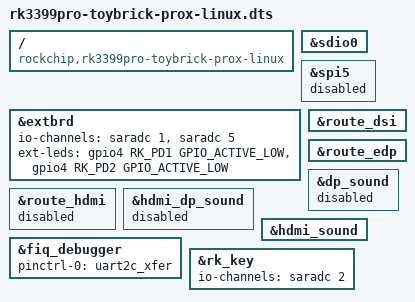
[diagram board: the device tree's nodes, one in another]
/*
 * Copyright (c) 2019 Fuzhou Rockchip Electronics Co., Ltd
 *
 * This file is dual-licensed: you can use it either under the terms
 * of the GPL or the X11 license, at your option. Note that this dual
 * licensing only applies to this file, and not this project as a
 * whole.
 *
 *  a) This file is free software; you can redistribute it and/or
 *     modify it under the terms of the GNU General Public License as
 *     published by the Free Software Foundation; either version 2 of the
 *     License, or (at your option) any later version.
 *
 *     This file is distributed in the hope that it will be useful,
 *     but WITHOUT ANY WARRANTY; without even the implied warranty of
 *     MERCHANTABILITY or FITNESS FOR A PARTICULAR PURPOSE.  See the
 *     GNU General Public License for more details.
 *
 * Or, alternatively,
 *
 *  b) Permission is hereby granted, free of charge, to any person
 *     obtaining a copy of this software and associated documentation
 *     files (the "Software"), to deal in the Software without
 *     restriction, including without limitation the rights to use,
 *     copy, modify, merge, publish, distribute, sublicense, and/or
 *     sell copies of the Software, and to permit persons to whom the
 *     Software is furnished to do so, subject to the following
 *     conditions:
 *
 *     The above copyright notice and this permission notice shall be
 *     included in all copies or substantial portions of the Software.
 *
 *     THE SOFTWARE IS PROVIDED "AS IS", WITHOUT WARRANTY OF ANY KIND,
 *     EXPRESS OR IMPLIED, INCLUDING BUT NOT LIMITED TO THE WARRANTIES
 *     OF MERCHANTABILITY, FITNESS FOR A PARTICULAR PURPOSE AND
 *     NONINFRINGEMENT. IN NO EVENT SHALL THE AUTHORS OR COPYRIGHT
 *     HOLDERS BE LIABLE FOR ANY CLAIM, DAMAGES OR OTHER LIABILITY,
 *     WHETHER IN AN ACTION OF CONTRACT, TORT OR OTHERWISE, ARISING
 *     FROM, OUT OF OR IN CONNECTION WITH THE SOFTWARE OR THE USE OR
 *     OTHER DEALINGS IN THE SOFTWARE.
 */

/dts-v1/;
#include "rk3399pro-toybrick-prox.dtsi"
#include "rk3399-android.dtsi"
#include "rk3399pro-toybrick-extboard.dtsi"
#include "rk3399pro-toybrick-prox-ov9750.dtsi"

/ {
	compatible = "rockchip,rk3399pro-toybrick-prox-linux","rockchip,rk3399pro";
};

&sdio0 {
	status = "okay";
};

&spi5 {
	status = "disabled";
};

&extbrd {
	status = "okay";
	io-channels = <&saradc 1>, <&saradc 5>;
	ext-leds = <&gpio4 RK_PD1 GPIO_ACTIVE_LOW>,    /* GPIO4_D1 */
			   <&gpio4 RK_PD2 GPIO_ACTIVE_LOW>;    /* GPIO4_D2 */
};

#if 0
&dfi {
	status = "okay";
};

&dmc {
	compatible = "rockchip,rk3399-dmc";
	devfreq-events = <&dfi>;
	interrupts = <GIC_SPI 1 IRQ_TYPE_LEVEL_HIGH 0>;
	clocks = <&cru SCLK_DDRCLK>;
	clock-names = "dmc_clk";
	ddr_timing = <&ddr_timing>;
	upthreshold = <40>;
	downdifferential = <20>;
	system-status-freq = <
		/*system status 		freq(KHz)*/
		SYS_STATUS_NORMAL		800000
		SYS_STATUS_REBOOT		528000
		SYS_STATUS_SUSPEND		200000
		SYS_STATUS_VIDEO_1080P	300000
		SYS_STATUS_VIDEO_4K 	600000
		SYS_STATUS_VIDEO_4K_10B 800000
		SYS_STATUS_PERFORMANCE	800000
		SYS_STATUS_BOOST		400000
		SYS_STATUS_DUALVIEW 	600000
		SYS_STATUS_ISP			600000
	>;
	auto-min-freq = <400000>;
	auto-freq-en = <1>;
	status = "okay";
};


&dmc_opp_table {
	compatible = "operating-points-v2";
	opp-200000000 {
		opp-hz = /bits/ 64 <200000000>;
		opp-microvolt = <825000>;
		status = "disabled";
	};
	opp-300000000 {
		opp-hz = /bits/ 64 <300000000>;
		opp-microvolt = <850000>;
		status = "disabled";
	};
	opp-400000000 {
		opp-hz = /bits/ 64 <400000000>;
		opp-microvolt = <900000>;
		status = "okay";
	};
	opp-528000000 {
		opp-hz = /bits/ 64 <528000000>;
		opp-microvolt = <900000>;
		status = "disabled";
	};
	opp-600000000 {
		opp-hz = /bits/ 64 <600000000>;
		opp-microvolt = <900000>;
		status = "disabled";
	};
	opp-800000000 {
		opp-hz = /bits/ 64 <800000000>;
		opp-microvolt = <900000>;
	};
};
#endif

&route_hdmi {
        status = "disabled";
};

&route_dsi {
        status = "okay";
};

&route_edp {
        status = "okay";
};

&dp_sound {
        status = "disabled";
};

&hdmi_dp_sound {
        status = "disabled";
};

&hdmi_sound {
        status = "okay";
};

&fiq_debugger {
        pinctrl-0 = <&uart2c_xfer>;
};

&rk_key {
        status = "okay";
        io-channels = <&saradc 2>;
        /delete-node/ power-key;
};
